AUTOSAR XML (schema 00046)
package /ComponentTypes
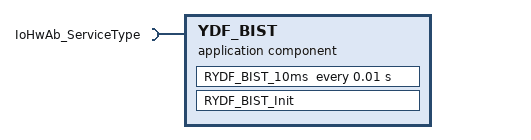
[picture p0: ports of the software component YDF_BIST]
  application sw component type YDF_BIST
    require port IoHwAb_ServiceType: required-interface=IoHwAb_ServiceType
      required-com-specs:
        IoHwAb_DioSetChannelVal
        IoHwAb_DioGetChannelVal
        IoHwAb_AdcReadValues
        IoHwAb_AdcGetChannelValue
        IoHwAb_AdcConvert12BitValueTomv
    behavior YDF_BIST_InternalBehavior
      init event RYDF_BIST_InitEvent: start-on-event=RYDF_BIST_Init
      timing event TMT_RYDF_BIST_10ms: start-on-event=RYDF_BIST_10ms, period=0.01
      runnable RYDF_BIST_Init
      runnable RYDF_BIST_10ms
        5 x sync call:
          SC_IoHwAb_ServiceType_IoHwAb_DioGetChannelVal: operation=IoHwAb_ServiceType.IoHwAb_DioGetChannelVal
          SC_IoHwAb_ServiceType_IoHwAb_DioSetChannelVal: operation=IoHwAb_ServiceType.IoHwAb_DioSetChannelVal
          SC_IoHwAb_ServiceType_IoHwAb_AdcConvert12BitValueTomv: operation=IoHwAb_ServiceType.IoHwAb_AdcConvert12BitValueTomv
          SC_IoHwAb_ServiceType_IoHwAb_AdcGetChannelValue: operation=IoHwAb_ServiceType.IoHwAb_AdcGetChannelValue
          SC_IoHwAb_ServiceType_IoHwAb_AdcReadValues: operation=IoHwAb_ServiceType.IoHwAb_AdcReadValues
  swc implementation YDF_BIST_Implementation: behavior=YDF_BIST_InternalBehavior
    code-descriptors:
      code Default: artifact-descriptors=autosar-engineering-object=category=SWSRC
